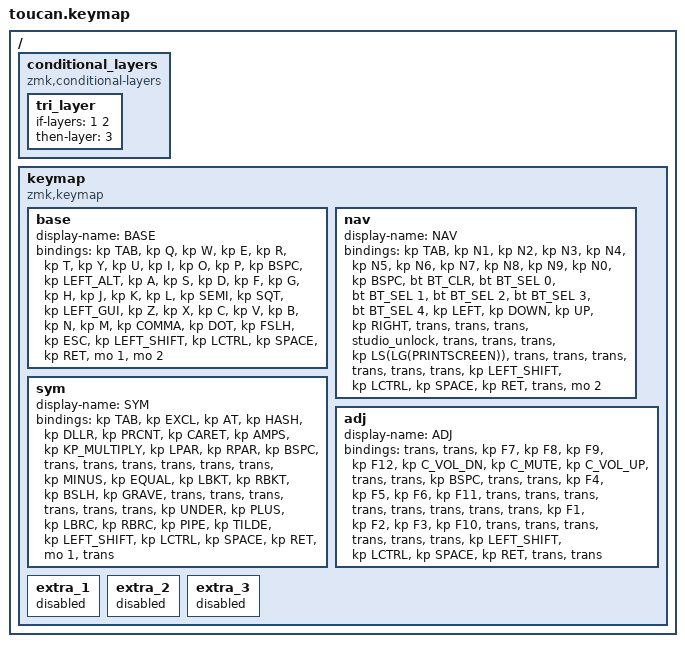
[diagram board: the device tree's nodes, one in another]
#include <behaviors.dtsi>
#include <dt-bindings/zmk/bt.h>
#include <dt-bindings/zmk/keys.h>

#define BASE 0
#define NAV  1
#define SYM  2
#define ADJ  3

/ {
    conditional_layers {
        compatible = "zmk,conditional-layers";

        tri_layer {
            if-layers = <1 2>;
            then-layer = <3>;
        };
    };

    keymap {
        compatible = "zmk,keymap";

        base {
            display-name = "BASE";
            bindings = <
&kp TAB  &kp Q  &kp W  &kp E  &kp R  &kp T  &kp Y  &kp U  &kp I  &kp O  &kp P  &kp BSPC  &kp LEFT_ALT  &kp A  &kp S  &kp D  &kp F  &kp G  &kp H  &kp J  &kp K  &kp L  &kp SEMI  &kp SQT  &kp LEFT_GUI  &kp Z  &kp X  &kp C  &kp V  &kp B  &kp N  &kp M  &kp COMMA  &kp DOT  &kp FSLH  &kp ESC  &kp LEFT_SHIFT  &kp LCTRL  &kp SPACE  &kp RET  &mo 1  &mo 2
            >;
        };

        nav {
            display-name = "NAV";
            bindings = <
&kp TAB  &kp N1  &kp N2  &kp N3  &kp N4  &kp N5  &kp N6  &kp N7  &kp N8  &kp N9  &kp N0  &kp BSPC  &bt BT_CLR  &bt BT_SEL 0  &bt BT_SEL 1  &bt BT_SEL 2  &bt BT_SEL 3  &bt BT_SEL 4  &kp LEFT  &kp DOWN  &kp UP  &kp RIGHT  &trans  &trans  &trans  &studio_unlock  &trans  &trans  &trans  &kp LS(LG(PRINTSCREEN))  &trans  &trans  &trans  &trans  &trans  &trans  &kp LEFT_SHIFT  &kp LCTRL  &kp SPACE  &kp RET  &trans  &mo 2
            >;
        };

        sym {
            display-name = "SYM";
            bindings = <
&kp TAB  &kp EXCL  &kp AT  &kp HASH  &kp DLLR  &kp PRCNT  &kp CARET  &kp AMPS  &kp KP_MULTIPLY  &kp LPAR  &kp RPAR  &kp BSPC  &trans  &trans  &trans  &trans  &trans  &trans  &kp MINUS  &kp EQUAL  &kp LBKT  &kp RBKT  &kp BSLH  &kp GRAVE  &trans  &trans  &trans  &trans  &trans  &trans  &kp UNDER  &kp PLUS  &kp LBRC  &kp RBRC  &kp PIPE  &kp TILDE  &kp LEFT_SHIFT  &kp LCTRL  &kp SPACE  &kp RET  &mo 1  &trans
            >;
        };

        adj {
            display-name = "ADJ";
            bindings = <
&trans  &trans  &kp F7  &kp F8  &kp F9  &kp F12  &kp C_VOL_DN  &kp C_MUTE  &kp C_VOL_UP  &trans  &trans  &kp BSPC  &trans  &trans  &kp F4  &kp F5  &kp F6  &kp F11  &trans  &trans  &trans  &trans  &trans  &trans  &trans  &trans  &kp F1  &kp F2  &kp F3  &kp F10  &trans  &trans  &trans  &trans  &trans  &trans  &kp LEFT_SHIFT  &kp LCTRL  &kp SPACE  &kp RET  &trans  &trans
            >;
        };

        extra_1 { status = "reserved"; };

        extra_2 { status = "reserved"; };

        extra_3 { status = "reserved"; };
    };
};
